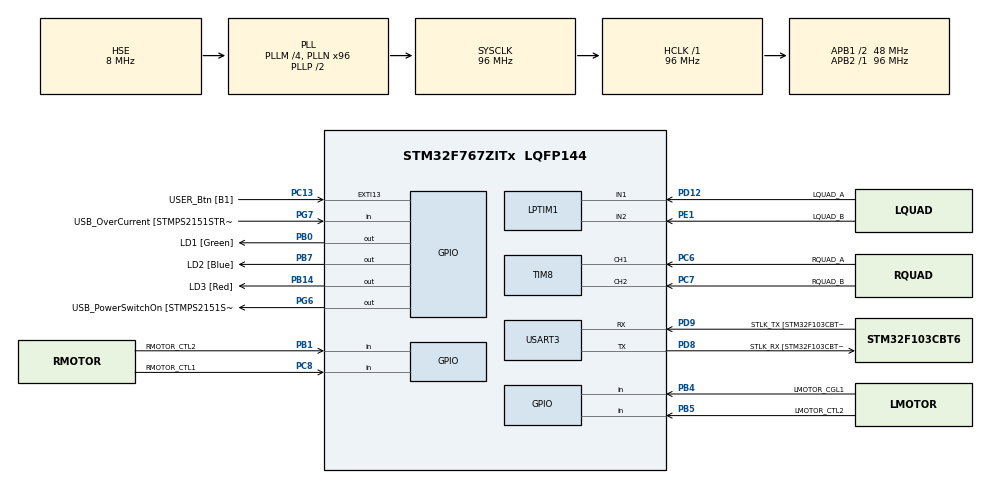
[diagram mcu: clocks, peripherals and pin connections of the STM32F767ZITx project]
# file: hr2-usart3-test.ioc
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PD12.GPIO_Label=LQUAD_A
Dma.USART3_RX.1.Mode=DMA_NORMAL
PB14.GPIO_Label=LD3 [Red]
PG6.GPIO_Label=USB_PowerSwitchOn [STMPS2151STR_EN]
PA14.GPIO_Label=TCK
PC6.GPIO_Label=RQUAD_A
PB13.Signal=ETH_TXD1
PG13.Signal=ETH_TXD0
RCC.SYSCLKSource=RCC_SYSCLKSOURCE_PLLCLK
USART3.VirtualMode-Asynchronous=VM_ASYNC
Dma.USART3_RX.1.Instance=DMA1_Stream1
RCC.APB2TimFreq_Value=96000000
PC7.Signal=S_TIM8_CH2
PH1/OSC_OUT.Signal=RCC_OSC_OUT
PD8.Signal=USART3_TX
PE1.Signal=LPTIM1_IN2
PC4.GPIO_Label=RMII_RXD0 [LAN8742A-CZ-TR_RXD0]
Dma.USART3_RX.1.Priority=DMA_PRIORITY_LOW
PB1.GPIO_Label=RMOTOR_CTL2
PA8.Signal=USB_OTG_FS_SOF
Dma.USART3_TX.0.MemDataAlignment=DMA_MDATAALIGN_BYTE
Mcu.Package=LQFP144
PB1.Signal=GPIO_Input
Dma.USART3_RX.1.FIFOMode=DMA_FIFOMODE_DISABLE
Dma.USART3_RX.1.Direction=DMA_PERIPH_TO_MEMORY
PD12.Signal=LPTIM1_IN1
PA10.Signal=USB_OTG_FS_ID
PC6.GPIO_PuPd=GPIO_PULLUP
Dma.USART3_TX.0.PeriphDataAlignment=DMA_PDATAALIGN_BYTE
RCC.APB1TimFreq_Value=96000000
PD9.GPIO_Label=STLK_TX [STM32F103CBT6_PA2]
Dma.USART3_TX.0.MemInc=DMA_MINC_ENABLE
PC13.Signal=GPXTI13
PA9.GPIO_Label=USB_VBUS
PE1.Mode=Encoder_mode_occur1
PC6.Signal=S_TIM8_CH1
Dma.USART3_RX.1.MemDataAlignment=DMA_MDATAALIGN_BYTE
PA11.GPIO_Label=USB_DM
PE1.GPIO_PuPd=GPIO_PULLUP
RCC.APB1CLKDivider=RCC_HCLK_DIV2
PG13.GPIO_Label=RMII_TXD0 [LAN8742A-CZ-TR_TXD0]
SH.S_TIM8_CH2.0=TIM8_CH2,Encoder_Interface
PA8.GPIO_Label=USB_SOF [TP1]
PA9.Signal=USB_OTG_FS_VBUS
PB4.GPIO_PuPd=GPIO_PULLDOWN
PC7.GPIO_PuPd=GPIO_PULLUP
PD8.Mode=Asynchronous
PB14.Signal=GPIO_Output
SH.S_TIM8_CH1.0=TIM8_CH1,Encoder_Interface
PE1.GPIO_Label=LQUAD_B
PB4.GPIO_Label=LMOTOR_CGL1
RCC.PRESCALERUSB=RCC_USBCLKSOURCE_PLL_DIV1_5
PG7.GPIO_Label=USB_OverCurrent [STMPS2151STR_FAULT]
PA1.GPIO_Label=RMII_REF_CLK [LAN8742A-CZ-TR_REFCLK0]
Dma.USART3_TX.0.Priority=DMA_PRIORITY_LOW
PA13.Mode=Serial_Wire
PC7.GPIO_Label=RQUAD_B
PC8.GPIO_PuPd=GPIO_PULLDOWN
PB5.Signal=GPIO_Input
PD12.Mode=Encoder_mode_occur1
PB5.GPIO_PuPd=GPIO_PULLDOWN
PA11.Signal=USB_OTG_FS_DM
ProjectManager.HeapSize=0x200
NVIC.PriorityGroup=NVIC_PRIORITYGROUP_4
PC15/OSC32_OUT.Signal=RCC_OSC32_OUT
PB0.Signal=GPIO_Output
PC1.Signal=ETH_MDC
Mcu.Family=STM32F7
NVIC.USART3_IRQn=true\:0\:0\:false\:false\:true\:true\:true
RCC.CortexFreq_Value=96000000
PG6.Signal=GPIO_Output
RCC.SYSCLKSourceVirtual=RCC_SYSCLKSOURCE_PLLCLK
TIM8.EncoderMode=TIM_ENCODERMODE_TI12
PB0.GPIO_Label=LD1 [Green]
PC14/OSC32_IN.Mode=LSE-External-Oscillator
PC13.GPIO_Label=USER_Btn [B1]
PB13.GPIO_Label=RMII_TXD1 [LAN8742A-CZ-TR_TXD1]
PD9.Mode=Asynchronous
PG11.Signal=ETH_TX_EN
ProjectManager.StackSize=0x400
PA12.Signal=USB_OTG_FS_DP
Dma.USART3_RX.1.MemInc=DMA_MINC_ENABLE
PH0/OSC_IN.Mode=HSE-External-Clock-Source
PB1.GPIO_PuPd=GPIO_PULLDOWN
RCC.HCLKFreq_Value=96000000
Dma.USART3_RX.1.PeriphDataAlignment=DMA_PDATAALIGN_BYTE
RCC.AHBFreq_Value=96000000
RCC.HSE_VALUE=8000000
RCC.PLLMUL=RCC_PLL_MUL9
PA14.Mode=Serial_Wire
PA10.GPIO_Label=USB_ID
Dma.USART3_TX.0.FIFOMode=DMA_FIFOMODE_DISABLE
PB7.Signal=GPIO_Output
Dma.USART3_TX.0.Mode=DMA_NORMAL
PH1/OSC_OUT.Mode=HSE-External-Clock-Source
Dma.USART3_TX.0.PeriphInc=DMA_PINC_DISABLE
PB7.GPIO_Label=LD2 [Blue]
PC14/OSC32_IN.Signal=RCC_OSC32_IN
PA2.GPIO_Label=RMII_MDIO [LAN8742A-CZ-TR_MDIO]
PB5.GPIO_Label=LMOTOR_CTL2
Dma.Request1=USART3_RX
PG11.GPIO_Label=RMII_TX_EN [LAN8742A-CZ-TR_TXEN]
PC5.Signal=ETH_RXD1
Dma.Request0=USART3_TX
PB4.Signal=GPIO_Input
PB3.GPIO_Label=SWO
RCC.PLLSourceVirtual=RCC_PLLSOURCE_HSE
Dma.USART3_TX.0.Instance=DMA1_Stream3
PG7.Signal=GPIO_Input
PC8.Signal=GPIO_Input
PC4.Signal=ETH_RXD0
PD9.Signal=USART3_RX
NVIC.DMA1_Stream1_IRQn=true\:0\:0\:false\:false\:true\:false\:true
Dma.USART3_TX.0.Direction=DMA_MEMORY_TO_PERIPH
PA12.GPIO_Label=USB_DP
PD8.GPIO_Label=STLK_RX [STM32F103CBT6_PA3]
PC8.GPIO_Label=RMOTOR_CTL1
PA13.Signal=SYS_JTMS-SWDIO
ProjectManager.TargetToolchain=STM32CubeIDE
RCC.USBFreq_Value=48000000
PA1.Signal=ETH_REF_CLK
board=NUCLEO-F767ZI
RCC.VCOOutputFreq_Value=192000000
PH0/OSC_IN.Signal=RCC_OSC_IN
RCC.APB2Freq_Value=96000000
PC1.GPIO_Label=RMII_MDC [LAN8742A-CZ-TR_MDC]
Mcu.Name=STM32F767ZITx
PA13.GPIO_Label=TMS
PA2.Signal=ETH_MDIO
RCC.48MHZClocksFreq_Value=24000000
PB3.Signal=SYS_JTDO-SWO
RCC.SYSCLKFreq_VALUE=96000000
PA7.GPIO_Label=RMII_CRS_DV [LAN8742A-CZ-TR_CRS_DV]
PC5.GPIO_Label=RMII_RXD1 [LAN8742A-CZ-TR_RXD1]
PC15/OSC32_OUT.Mode=LSE-External-Oscillator
PA14.Signal=SYS_JTCK-SWCLK
RCC.HSI_VALUE=16000000
PH0/OSC_IN.GPIO_Label=MCO [STM32F103CBT6_PA8]
RCC.PLLQ=4
RCC.PLLM=4
RCC.PLLN=96
NVIC.DMA1_Stream3_IRQn=true\:0\:0\:false\:false\:true\:false\:true
RCC.APB1Freq_Value=48000000
Dma.USART3_RX.1.PeriphInc=DMA_PINC_DISABLE
PD12.GPIO_PuPd=GPIO_PULLUP
PA7.Signal=ETH_CRS_DV

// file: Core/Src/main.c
/* USER CODE BEGIN Header */
/**
  ******************************************************************************
  * @file           : main.c
  * @brief          : Main program body
  ******************************************************************************
  * @attention
  *
  * <h2><center>&copy; Copyright (c) 2020 STMicroelectronics.
  * All rights reserved.</center></h2>
  *
  * This software component is licensed by ST under BSD 3-Clause license,
  * the "License"; You may not use this file except in compliance with the
  * License. You may obtain a copy of the License at:
  *                        opensource.org/licenses/BSD-3-Clause
  *
  ******************************************************************************
  */
/* USER CODE END Header */
#include "main.h"
#include "dma.h"
#include "lptim.h"
#include "tim.h"
#include "usart.h"
#include "gpio.h"

/* USER CODE BEGIN Includes */
#include <stdio.h>
#include "retarget.h"
#include "stm32f7xx_hal_uart.h"
/* USER CODE END Includes */

void SystemClock_Config(void);

int main(void)
{

  /* MCU Configuration--------------------------------------------------------*/

  /* Reset of all peripherals, Initializes the Flash interface and the Systick. */
  HAL_Init();

  /* Configure the system clock */
  SystemClock_Config();

  /* Initialize all configured peripherals */
  MX_GPIO_Init();
  MX_DMA_Init();
  MX_USART3_UART_Init();
  MX_TIM8_Init();
  MX_LPTIM1_Init();
  /* USER CODE BEGIN 2 */
  // Use UART3 for stdio
  RetargetInit(&huart3);
  /* USER CODE END 2 */

  /* Infinite loop */
  /* USER CODE BEGIN WHILE */
  HAL_TIM_Encoder_Start(&htim8,TIM_CHANNEL_ALL);
  HAL_LPTIM_Encoder_Start(&hlptim1,65535L);
  uint8_t c;
  // uint8_t i = 0;
  while (1)
  {
    /* USER CODE END WHILE */

    /* USER CODE BEGIN 3 */
	// Read right and left encoder counts
	HAL_UART_Receive(&huart3, &c, 1, 0xffffffff);
	HAL_GPIO_TogglePin(LD1_GPIO_Port, LD1_Pin);
	HAL_GPIO_TogglePin(LD2_GPIO_Port, LD2_Pin);
	HAL_GPIO_TogglePin(LD3_GPIO_Port, LD3_Pin);
	HAL_UART_Transmit(&huart3, &c, 1, 100);
	HAL_UART_Transmit(&huart3, &c, 1, 100);
	// c = (i == 0 ? '\r' : (i == 1 ? '\n' : ' ' + i));
	// HAL_UART_Transmit(&huart3, &c, 1, 100);
	// i = (i + 1) & 0x3f;
	// HAL_Delay(100);
  }
  /* USER CODE END 3 */
}

void SystemClock_Config(void)
{
  RCC_OscInitTypeDef RCC_OscInitStruct = {0};
  RCC_ClkInitTypeDef RCC_ClkInitStruct = {0};
  RCC_PeriphCLKInitTypeDef PeriphClkInitStruct = {0};

  /** Configure LSE Drive Capability
  */
  HAL_PWR_EnableBkUpAccess();
  /** Configure the main internal regulator output voltage
  */
  __HAL_RCC_PWR_CLK_ENABLE();
  __HAL_PWR_VOLTAGESCALING_CONFIG(PWR_REGULATOR_VOLTAGE_SCALE3);
  /** Initializes the RCC Oscillators according to the specified parameters
  * in the RCC_OscInitTypeDef structure.
  */
  RCC_OscInitStruct.OscillatorType = RCC_OSCILLATORTYPE_HSE;
  RCC_OscInitStruct.HSEState = RCC_HSE_BYPASS;
  RCC_OscInitStruct.PLL.PLLState = RCC_PLL_ON;
  RCC_OscInitStruct.PLL.PLLSource = RCC_PLLSOURCE_HSE;
  RCC_OscInitStruct.PLL.PLLM = 4;
  RCC_OscInitStruct.PLL.PLLN = 96;
  RCC_OscInitStruct.PLL.PLLP = RCC_PLLP_DIV2;
  RCC_OscInitStruct.PLL.PLLQ = 4;
  if (HAL_RCC_OscConfig(&RCC_OscInitStruct) != HAL_OK)
  {
    Error_Handler();
  }
  /** Activate the Over-Drive mode
  */
  if (HAL_PWREx_EnableOverDrive() != HAL_OK)
  {
    Error_Handler();
  }
  /** Initializes the CPU, AHB and APB buses clocks
  */
  RCC_ClkInitStruct.ClockType = RCC_CLOCKTYPE_HCLK|RCC_CLOCKTYPE_SYSCLK
                              |RCC_CLOCKTYPE_PCLK1|RCC_CLOCKTYPE_PCLK2;
  RCC_ClkInitStruct.SYSCLKSource = RCC_SYSCLKSOURCE_PLLCLK;
  RCC_ClkInitStruct.AHBCLKDivider = RCC_SYSCLK_DIV1;
  RCC_ClkInitStruct.APB1CLKDivider = RCC_HCLK_DIV2;
  RCC_ClkInitStruct.APB2CLKDivider = RCC_HCLK_DIV1;

  if (HAL_RCC_ClockConfig(&RCC_ClkInitStruct, FLASH_LATENCY_3) != HAL_OK)
  {
    Error_Handler();
  }
  PeriphClkInitStruct.PeriphClockSelection = RCC_PERIPHCLK_USART3|RCC_PERIPHCLK_LPTIM1;
  PeriphClkInitStruct.Usart3ClockSelection = RCC_USART3CLKSOURCE_PCLK1;
  PeriphClkInitStruct.Lptim1ClockSelection = RCC_LPTIM1CLKSOURCE_PCLK;
  if (HAL_RCCEx_PeriphCLKConfig(&PeriphClkInitStruct) != HAL_OK)
  {
    Error_Handler();
  }
}

void Error_Handler(void)
{
  __disable_irq();
  while (1)
  {
  }
}

/************************ (C) COPYRIGHT STMicroelectronics *****END OF FILE****/
